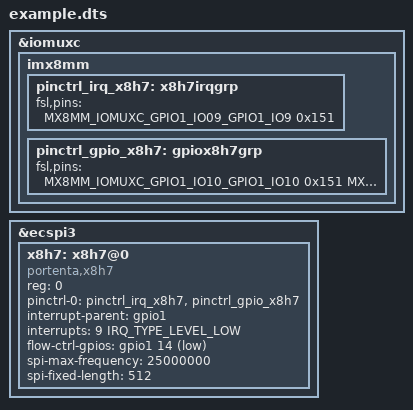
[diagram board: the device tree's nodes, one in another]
&iomuxc {
	imx8mm {
		pinctrl_irq_x8h7: x8h7irqgrp {
			fsl,pins = <
				/* H7 interrupt pin active low, pullup */
				MX8MM_IOMUXC_GPIO1_IO09_GPIO1_IO9		0x151 /* PC1_STM32 */
			>;
		};

		pinctrl_gpio_x8h7: gpiox8h7grp {
			fsl,pins = <
				MX8MM_IOMUXC_GPIO1_IO10_GPIO1_IO10		0x151 /* NRST_STM32 Pull Up */
				MX8MM_IOMUXC_GPIO1_IO11_GPIO1_IO11		0x110 /* BOOT0_STM32 Pull Down */
				MX8MM_IOMUXC_GPIO1_IO08_GPIO1_IO8		0x110 /* SWDIO_STM32 Pull Down */
				MX8MM_IOMUXC_GPIO1_IO15_GPIO1_IO15		0x110 /* SWCLK_STM32 Pull Down */
				MX8MM_IOMUXC_GPIO1_IO07_GPIO1_IO7		0x110 /* PA0_STM32 Pull Down M4 led red */
				MX8MM_IOMUXC_GPIO1_IO14_GPIO1_IO14		0x151 /* PE5_STM32 Pull Up */
			>;
		};
	};
};

&ecspi3 {
	status = "okay";

	x8h7: x8h7@0 {
		#address-cells = <1>;
		#size-cells = <1>;
		compatible = "portenta,x8h7";
		reg = <0>;
		pinctrl-names = "default";
		pinctrl-0 = <&pinctrl_irq_x8h7>, <&pinctrl_gpio_x8h7>;
		interrupt-parent = <&gpio1>;
		interrupts = <9 IRQ_TYPE_LEVEL_LOW>;
		flow-ctrl-gpios = <&gpio1 14 GPIO_ACTIVE_LOW>;
		spi-max-frequency = <25000000>;
		spi-fixed-length = <512>;
	};
};
